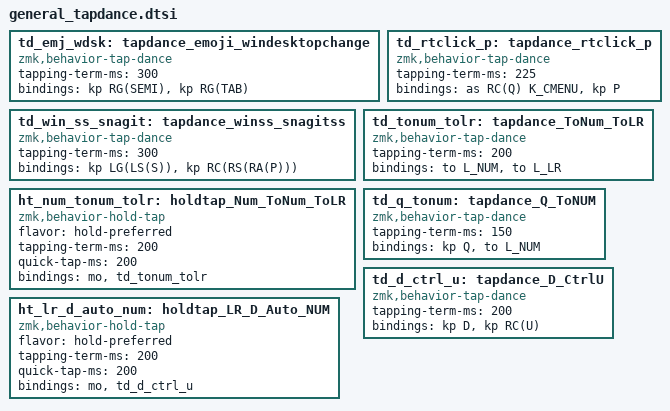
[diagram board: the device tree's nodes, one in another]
/*****************************************************************************************************
 *  TAP DANCE configurations
 *  for general cases

    // INCLUDE THIS inside Behaviors section of Keymap where other dependencies already pre-included
    
 *****************************************************************************************************/
#include <dt-bindings/zmk/keys.h>

td_emj_wdsk: tapdance_emoji_windesktopchange {
    compatible = "zmk,behavior-tap-dance";
    #binding-cells = <0>;
    tapping-term-ms = <300>;
    bindings = <&kp RG(SEMI)>, <&kp RG(TAB)>; // [1x] Win+; (Emoji pop-up)    [2x] Win+Tab (Windows desktops)
};


td_win_ss_snagit: tapdance_winss_snagitss {
    compatible = "zmk,behavior-tap-dance";
    #binding-cells = <0>;
    tapping-term-ms = <300>;
    bindings = <&kp LG(LS(S))>, <&kp RC(RS(RA(P)))>;  // [1x] Win+Shift+S   [2x] Ctrl+Shift+Alt+P (customized in SnagIt settings)
};

// 2024-07-23 special for 2x-tap 'Menu-key' to add "P" [for OneNote when rt-click on a paragraph; to get link to paragraph]
// 1st-tap is an AutoShift(hold) case - SO...
// 1-tap: rt-click menu; 2-tap: "P"; Hold: Ctrl+Q
td_rtclick_p: tapdance_rtclick_p {
    compatible = "zmk,behavior-tap-dance";
    #binding-cells = <0>;
    tapping-term-ms = <225>;
    bindings = <&as RC(Q) K_CMENU>, <&kp P>; 
};


// **************************************************
// goal: hold = NUM; [1x] >NUM; [2x] >LR
// TRY 4: tap-dance for &to <layer-first-tap>; &to <layer-2nd-tap>
// ref: https://www.reddit.com/r/zmk/comments/1ajmjl6/tapdance_with_nested_mt_leads_to_delay_until/
// think all terms-ms need to match?
// NOTE: HT always takes 2 args / so use like "ht_num_tonum_tolr L_NUM 0"
// NOTE: need 'plain' parms for hold-tap; so pass in the NUM layer in keymap not here: "<&mo>" here not "<&mo LAYER>" ==> then in keymap: "&macro LNUM 0"

td_tonum_tolr: tapdance_ToNum_ToLR {
    compatible = "zmk,behavior-tap-dance";
    #binding-cells = <0>;
    tapping-term-ms = <200>;
    bindings = <&to L_NUM>, <&to L_LR>; // 1x: to NUM, 2x: to LR
};

ht_num_tonum_tolr: holdtap_Num_ToNum_ToLR {
    compatible = "zmk,behavior-hold-tap";
    #binding-cells = <2>;
    flavor = "hold-preferred"; // which?
    tapping-term-ms = <200>;
    quick-tap-ms = <200>;
    bindings = <&mo>, <&td_tonum_tolr>;
    //retro-tap; // need this?
    // 2024-08-26 changed to "hold-preferred" and removed "retro-tap" / then worked / Ø sure if needed both
};

td_q_tonum: tapdance_Q_ToNUM {
    compatible = "zmk,behavior-tap-dance";
    #binding-cells = <0>;
    tapping-term-ms = <150>;
    bindings = <&kp Q>, <&to L_NUM>; // 1x: q, 2x: to NUM layer
};

// similar as above but for D and Lightroom: Hold=NUM, Tap=D, 2-Tap=(Ctrl+U)
td_d_ctrl_u: tapdance_D_CtrlU {
    compatible = "zmk,behavior-tap-dance";
    #binding-cells = <0>;
    tapping-term-ms = <200>;
    bindings = <&kp D>, <&kp RC(U)>; // 1st tap - D (LR: develop), 2x tap - Ctrl+U (LR: auto-develop settings)
};

ht_lr_d_auto_num: holdtap_LR_D_Auto_NUM {
    compatible = "zmk,behavior-hold-tap";
    #binding-cells = <2>;
    flavor = "hold-preferred"; // which?
    tapping-term-ms = <200>;
    quick-tap-ms = <200>;
    bindings = <&mo>, <&td_d_ctrl_u>;
};

